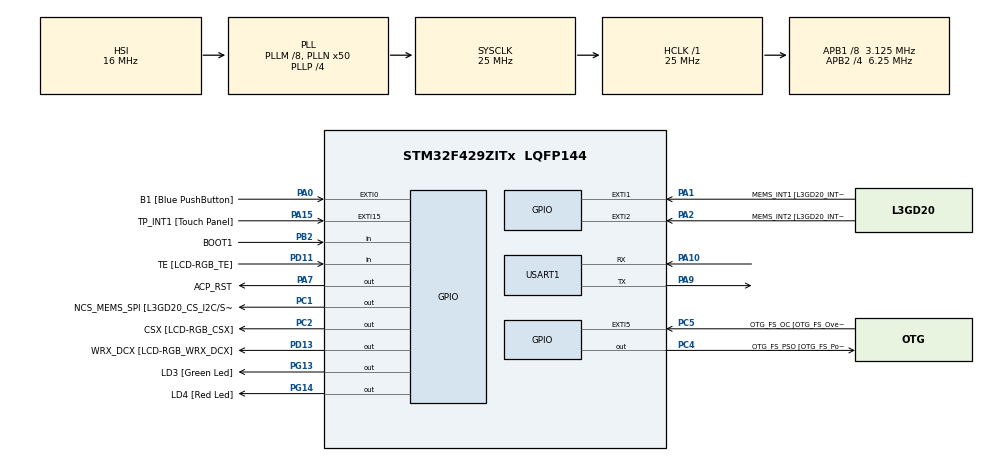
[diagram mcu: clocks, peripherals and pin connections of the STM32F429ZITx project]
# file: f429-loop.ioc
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Dma.Request0=USART1_TX
Dma.Request1=USART1_RX
Dma.USART1_RX.1.Direction=DMA_PERIPH_TO_MEMORY
Dma.USART1_RX.1.FIFOMode=DMA_FIFOMODE_DISABLE
Dma.USART1_RX.1.Instance=DMA2_Stream2
Dma.USART1_RX.1.MemDataAlignment=DMA_MDATAALIGN_BYTE
Dma.USART1_RX.1.MemInc=DMA_MINC_ENABLE
Dma.USART1_RX.1.Mode=DMA_CIRCULAR
Dma.USART1_RX.1.PeriphDataAlignment=DMA_PDATAALIGN_BYTE
Dma.USART1_RX.1.PeriphInc=DMA_PINC_DISABLE
Dma.USART1_RX.1.Priority=DMA_PRIORITY_LOW
Dma.USART1_TX.0.Direction=DMA_MEMORY_TO_PERIPH
Dma.USART1_TX.0.FIFOMode=DMA_FIFOMODE_DISABLE
Dma.USART1_TX.0.Instance=DMA2_Stream7
Dma.USART1_TX.0.MemDataAlignment=DMA_MDATAALIGN_BYTE
Dma.USART1_TX.0.MemInc=DMA_MINC_ENABLE
Dma.USART1_TX.0.Mode=DMA_NORMAL
Dma.USART1_TX.0.PeriphDataAlignment=DMA_PDATAALIGN_BYTE
Dma.USART1_TX.0.PeriphInc=DMA_PINC_DISABLE
Dma.USART1_TX.0.Priority=DMA_PRIORITY_LOW
Mcu.Family=STM32F4
Mcu.Name=STM32F429ZITx
Mcu.Package=LQFP144
NVIC.DMA2_Stream2_IRQn=true\:0\:0\:false\:false\:true\:false\:true\:true
NVIC.DMA2_Stream7_IRQn=true\:0\:0\:false\:false\:true\:false\:true\:true
NVIC.PriorityGroup=NVIC_PRIORITYGROUP_0
NVIC.TIM6_DAC_IRQn=true\:0\:0\:false\:false\:true\:true\:true\:true
NVIC.USART1_IRQn=true\:0\:0\:false\:false\:true\:true\:true\:true
PA0/WKUP.GPIO_Label=B1 [Blue PushButton]
PA0/WKUP.GPIO_ModeDefaultEXTI=GPIO_MODE_EVT_RISING
PA0/WKUP.GPIO_PuPd=GPIO_NOPULL
PA0/WKUP.Signal=GPXTI0
PA1.GPIO_Label=MEMS_INT1 [L3GD20_INT1]
PA1.GPIO_ModeDefaultEXTI=GPIO_MODE_EVT_RISING
PA1.GPIO_PuPd=GPIO_NOPULL
PA1.Signal=GPXTI1
PA10.Mode=Asynchronous
PA10.Signal=USART1_RX
PA15.GPIO_Label=TP_INT1 [Touch Panel]
PA15.GPIO_ModeDefaultEXTI=GPIO_MODE_EVT_RISING
PA15.GPIO_PuPd=GPIO_NOPULL
PA15.Signal=GPXTI15
PA2.GPIO_Label=MEMS_INT2 [L3GD20_INT2]
PA2.GPIO_ModeDefaultEXTI=GPIO_MODE_EVT_RISING
PA2.GPIO_PuPd=GPIO_NOPULL
PA2.Signal=GPXTI2
PA7.GPIO_Label=ACP_RST
PA7.GPIO_Mode=GPIO_MODE_OUTPUT_PP
PA7.GPIO_PuPd=GPIO_NOPULL
PA7.GPIO_Speed=GPIO_SPEED_FREQ_LOW
PA7.Signal=GPIO_Output
PA9.Mode=Asynchronous
PA9.Signal=USART1_TX
PB2/BOOT1.GPIO_Label=BOOT1
PB2/BOOT1.GPIO_Mode=GPIO_MODE_INPUT
PB2/BOOT1.GPIO_PuPd=GPIO_NOPULL
PB2/BOOT1.Signal=GPIO_Input
PC1.GPIO_Label=NCS_MEMS_SPI [L3GD20_CS_I2C/SPI]
PC1.GPIO_Mode=GPIO_MODE_OUTPUT_PP
PC1.GPIO_PuPd=GPIO_NOPULL
PC1.GPIO_Speed=GPIO_SPEED_FREQ_LOW
PC1.Signal=GPIO_Output
PC2.GPIO_Label=CSX [LCD-RGB_CSX]
PC2.GPIO_Mode=GPIO_MODE_OUTPUT_PP
PC2.GPIO_PuPd=GPIO_NOPULL
PC2.GPIO_Speed=GPIO_SPEED_FREQ_LOW
PC2.Signal=GPIO_Output
PC4.GPIO_Label=OTG_FS_PSO [OTG_FS_PowerSwitchOn]
PC4.GPIO_Mode=GPIO_MODE_OUTPUT_PP
PC4.GPIO_PuPd=GPIO_NOPULL
PC4.GPIO_Speed=GPIO_SPEED_FREQ_LOW
PC4.Signal=GPIO_Output
PC5.GPIO_Label=OTG_FS_OC [OTG_FS_OverCurrent]
PC5.GPIO_ModeDefaultEXTI=GPIO_MODE_EVT_RISING
PC5.Signal=GPXTI5
PD11.GPIO_Label=TE [LCD-RGB_TE]
PD11.GPIO_Mode=GPIO_MODE_INPUT
PD11.GPIO_PuPd=GPIO_NOPULL
PD11.Signal=GPIO_Input
PD13.GPIO_Label=WRX_DCX [LCD-RGB_WRX_DCX]
PD13.GPIO_Mode=GPIO_MODE_OUTPUT_PP
PD13.GPIO_PuPd=GPIO_NOPULL
PD13.GPIO_Speed=GPIO_SPEED_FREQ_LOW
PD13.Signal=GPIO_Output
PG13.GPIO_Label=LD3 [Green Led]
PG13.GPIO_Mode=GPIO_MODE_OUTPUT_PP
PG13.GPIO_PuPd=GPIO_NOPULL
PG13.GPIO_Speed=GPIO_SPEED_FREQ_LOW
PG13.Signal=GPIO_Output
PG14.GPIO_Label=LD4 [Red Led]
PG14.GPIO_Mode=GPIO_MODE_OUTPUT_PP
PG14.GPIO_PuPd=GPIO_NOPULL
PG14.GPIO_Speed=GPIO_SPEED_FREQ_LOW
PG14.Signal=GPIO_Output
ProjectManager.HeapSize=0x200
ProjectManager.StackSize=0x400
ProjectManager.TargetToolchain=STM32CubeIDE
RCC.48MHZClocksFreq_Value=14285714.285714285
RCC.AHBFreq_Value=25000000
RCC.APB1CLKDivider=RCC_HCLK_DIV8
RCC.APB1Freq_Value=3125000
RCC.APB1TimFreq_Value=6250000
RCC.APB2CLKDivider=RCC_HCLK_DIV4
RCC.APB2Freq_Value=6250000
RCC.APB2TimFreq_Value=12500000
RCC.CortexFreq_Value=25000000
RCC.HCLKFreq_Value=25000000
RCC.HSE_VALUE=8000000
RCC.HSI_VALUE=16000000
RCC.LSE_VALUE=32768
RCC.PLLM=8
RCC.PLLN=50
RCC.PLLP=RCC_PLLP_DIV4
RCC.PLLQ=7
RCC.SYSCLKFreq_VALUE=25000000
RCC.SYSCLKSource=RCC_SYSCLKSOURCE_PLLCLK
RCC.VCOOutputFreq_Value=100000000
TIM6.Period=24999
USART1.VirtualMode=VM_ASYNC
VP_TIM6_VS_ClockSourceINT.Mode=Enable_Timer
board=STM32F429I-DISC1

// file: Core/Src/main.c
/* USER CODE BEGIN Header */
/**
  ******************************************************************************
  * @file           : main.c
  * @brief          : Main program body
  ******************************************************************************
  * @attention
  *
  * Copyright (c) 2026 STMicroelectronics.
  * All rights reserved.
  *
  * This software is licensed under terms that can be found in the LICENSE file
  * in the root directory of this software component.
  * If no LICENSE file comes with this software, it is provided AS-IS.
  *
  ******************************************************************************
  */
/* USER CODE END Header */
#include "main.h"

/* USER CODE BEGIN Includes */
#include "superloop.h"
extern int board_init(void);
/* USER CODE END Includes */

TIM_HandleTypeDef htim6;

UART_HandleTypeDef huart1;
DMA_HandleTypeDef hdma_usart1_tx;
DMA_HandleTypeDef hdma_usart1_rx;

void SystemClock_Config(void);
static void MX_GPIO_Init(void);
static void MX_DMA_Init(void);
static void MX_USART1_UART_Init(void);
static void MX_TIM6_Init(void);

int main(void)
{

  /* MCU Configuration--------------------------------------------------------*/

  /* Reset of all peripherals, Initializes the Flash interface and the Systick. */
  HAL_Init();

  /* Configure the system clock */
  SystemClock_Config();

  /* Initialize all configured peripherals */
  MX_GPIO_Init();
  MX_DMA_Init();
  MX_USART1_UART_Init();
  MX_TIM6_Init();
  /* USER CODE BEGIN 2 */
  board_init();
  /* USER CODE END 2 */

  /* Infinite loop */
  while (1)
  {

    /* USER CODE BEGIN 3 */
    sloop_dispatch();
  }
  /* USER CODE END 3 */
}

void SystemClock_Config(void)
{
  RCC_OscInitTypeDef RCC_OscInitStruct = {0};
  RCC_ClkInitTypeDef RCC_ClkInitStruct = {0};

  /** Configure the main internal regulator output voltage
  */
  __HAL_RCC_PWR_CLK_ENABLE();
  __HAL_PWR_VOLTAGESCALING_CONFIG(PWR_REGULATOR_VOLTAGE_SCALE3);

  /** Initializes the RCC Oscillators according to the specified parameters
  * in the RCC_OscInitTypeDef structure.
  */
  RCC_OscInitStruct.OscillatorType = RCC_OSCILLATORTYPE_HSI;
  RCC_OscInitStruct.HSIState = RCC_HSI_ON;
  RCC_OscInitStruct.HSICalibrationValue = RCC_HSICALIBRATION_DEFAULT;
  RCC_OscInitStruct.PLL.PLLState = RCC_PLL_ON;
  RCC_OscInitStruct.PLL.PLLSource = RCC_PLLSOURCE_HSI;
  RCC_OscInitStruct.PLL.PLLM = 8;
  RCC_OscInitStruct.PLL.PLLN = 50;
  RCC_OscInitStruct.PLL.PLLP = RCC_PLLP_DIV4;
  RCC_OscInitStruct.PLL.PLLQ = 7;
  if (HAL_RCC_OscConfig(&RCC_OscInitStruct) != HAL_OK)
  {
    Error_Handler();
  }

  /** Initializes the CPU, AHB and APB buses clocks
  */
  RCC_ClkInitStruct.ClockType = RCC_CLOCKTYPE_HCLK|RCC_CLOCKTYPE_SYSCLK
                              |RCC_CLOCKTYPE_PCLK1|RCC_CLOCKTYPE_PCLK2;
  RCC_ClkInitStruct.SYSCLKSource = RCC_SYSCLKSOURCE_PLLCLK;
  RCC_ClkInitStruct.AHBCLKDivider = RCC_SYSCLK_DIV1;
  RCC_ClkInitStruct.APB1CLKDivider = RCC_HCLK_DIV8;
  RCC_ClkInitStruct.APB2CLKDivider = RCC_HCLK_DIV4;

  if (HAL_RCC_ClockConfig(&RCC_ClkInitStruct, FLASH_LATENCY_0) != HAL_OK)
  {
    Error_Handler();
  }
}

static void MX_TIM6_Init(void)
{

  TIM_MasterConfigTypeDef sMasterConfig = {0};

  htim6.Instance = TIM6;
  htim6.Init.Prescaler = 0;
  htim6.Init.CounterMode = TIM_COUNTERMODE_UP;
  htim6.Init.Period = 24999;
  htim6.Init.AutoReloadPreload = TIM_AUTORELOAD_PRELOAD_DISABLE;
  if (HAL_TIM_Base_Init(&htim6) != HAL_OK)
  {
    Error_Handler();
  }
  sMasterConfig.MasterOutputTrigger = TIM_TRGO_RESET;
  sMasterConfig.MasterSlaveMode = TIM_MASTERSLAVEMODE_DISABLE;
  if (HAL_TIMEx_MasterConfigSynchronization(&htim6, &sMasterConfig) != HAL_OK)
  {
    Error_Handler();
  }

}

static void MX_USART1_UART_Init(void)
{

  huart1.Instance = USART1;
  huart1.Init.BaudRate = 115200;
  huart1.Init.WordLength = UART_WORDLENGTH_8B;
  huart1.Init.StopBits = UART_STOPBITS_1;
  huart1.Init.Parity = UART_PARITY_NONE;
  huart1.Init.Mode = UART_MODE_TX_RX;
  huart1.Init.HwFlowCtl = UART_HWCONTROL_NONE;
  huart1.Init.OverSampling = UART_OVERSAMPLING_16;
  if (HAL_UART_Init(&huart1) != HAL_OK)
  {
    Error_Handler();
  }

}

static void MX_DMA_Init(void)
{

  /* DMA controller clock enable */
  __HAL_RCC_DMA2_CLK_ENABLE();

  /* DMA interrupt init */
  /* DMA2_Stream2_IRQn interrupt configuration */
  HAL_NVIC_SetPriority(DMA2_Stream2_IRQn, 0, 0);
  HAL_NVIC_EnableIRQ(DMA2_Stream2_IRQn);
  /* DMA2_Stream7_IRQn interrupt configuration */
  HAL_NVIC_SetPriority(DMA2_Stream7_IRQn, 0, 0);
  HAL_NVIC_EnableIRQ(DMA2_Stream7_IRQn);

}

static void MX_GPIO_Init(void)
{
  GPIO_InitTypeDef GPIO_InitStruct = {0};

  /* GPIO Ports Clock Enable */
  __HAL_RCC_GPIOC_CLK_ENABLE();
  __HAL_RCC_GPIOA_CLK_ENABLE();
  __HAL_RCC_GPIOB_CLK_ENABLE();
  __HAL_RCC_GPIOD_CLK_ENABLE();
  __HAL_RCC_GPIOG_CLK_ENABLE();

  /*Configure GPIO pin Output Level */
  HAL_GPIO_WritePin(GPIOC, NCS_MEMS_SPI_Pin|CSX_Pin|OTG_FS_PSO_Pin, GPIO_PIN_RESET);

  /*Configure GPIO pin Output Level */
  HAL_GPIO_WritePin(ACP_RST_GPIO_Port, ACP_RST_Pin, GPIO_PIN_RESET);

  /*Configure GPIO pin Output Level */
  HAL_GPIO_WritePin(WRX_DCX_GPIO_Port, WRX_DCX_Pin, GPIO_PIN_RESET);

  /*Configure GPIO pin Output Level */
  HAL_GPIO_WritePin(GPIOG, LD3_Pin|LD4_Pin, GPIO_PIN_RESET);

  /*Configure GPIO pins : NCS_MEMS_SPI_Pin CSX_Pin OTG_FS_PSO_Pin */
  GPIO_InitStruct.Pin = NCS_MEMS_SPI_Pin|CSX_Pin|OTG_FS_PSO_Pin;
  GPIO_InitStruct.Mode = GPIO_MODE_OUTPUT_PP;
  GPIO_InitStruct.Pull = GPIO_NOPULL;
  GPIO_InitStruct.Speed = GPIO_SPEED_FREQ_LOW;
  HAL_GPIO_Init(GPIOC, &GPIO_InitStruct);

  /*Configure GPIO pins : B1_Pin MEMS_INT1_Pin MEMS_INT2_Pin TP_INT1_Pin */
  GPIO_InitStruct.Pin = B1_Pin|MEMS_INT1_Pin|MEMS_INT2_Pin|TP_INT1_Pin;
  GPIO_InitStruct.Mode = GPIO_MODE_EVT_RISING;
  GPIO_InitStruct.Pull = GPIO_NOPULL;
  HAL_GPIO_Init(GPIOA, &GPIO_InitStruct);

  /*Configure GPIO pin : ACP_RST_Pin */
  GPIO_InitStruct.Pin = ACP_RST_Pin;
  GPIO_InitStruct.Mode = GPIO_MODE_OUTPUT_PP;
  GPIO_InitStruct.Pull = GPIO_NOPULL;
  GPIO_InitStruct.Speed = GPIO_SPEED_FREQ_LOW;
  HAL_GPIO_Init(ACP_RST_GPIO_Port, &GPIO_InitStruct);

  /*Configure GPIO pin : OTG_FS_OC_Pin */
  GPIO_InitStruct.Pin = OTG_FS_OC_Pin;
  GPIO_InitStruct.Mode = GPIO_MODE_EVT_RISING;
  GPIO_InitStruct.Pull = GPIO_NOPULL;
  HAL_GPIO_Init(OTG_FS_OC_GPIO_Port, &GPIO_InitStruct);

  /*Configure GPIO pin : BOOT1_Pin */
  GPIO_InitStruct.Pin = BOOT1_Pin;
  GPIO_InitStruct.Mode = GPIO_MODE_INPUT;
  GPIO_InitStruct.Pull = GPIO_NOPULL;
  HAL_GPIO_Init(BOOT1_GPIO_Port, &GPIO_InitStruct);

  /*Configure GPIO pin : TE_Pin */
  GPIO_InitStruct.Pin = TE_Pin;
  GPIO_InitStruct.Mode = GPIO_MODE_INPUT;
  GPIO_InitStruct.Pull = GPIO_NOPULL;
  HAL_GPIO_Init(TE_GPIO_Port, &GPIO_InitStruct);

  /*Configure GPIO pin : WRX_DCX_Pin */
  GPIO_InitStruct.Pin = WRX_DCX_Pin;
  GPIO_InitStruct.Mode = GPIO_MODE_OUTPUT_PP;
  GPIO_InitStruct.Pull = GPIO_NOPULL;
  GPIO_InitStruct.Speed = GPIO_SPEED_FREQ_LOW;
  HAL_GPIO_Init(WRX_DCX_GPIO_Port, &GPIO_InitStruct);

  /*Configure GPIO pins : LD3_Pin LD4_Pin */
  GPIO_InitStruct.Pin = LD3_Pin|LD4_Pin;
  GPIO_InitStruct.Mode = GPIO_MODE_OUTPUT_PP;
  GPIO_InitStruct.Pull = GPIO_NOPULL;
  GPIO_InitStruct.Speed = GPIO_SPEED_FREQ_LOW;
  HAL_GPIO_Init(GPIOG, &GPIO_InitStruct);

}

/* USER CODE BEGIN 4 */
void HAL_SYSTICK_Callback(void)
{
	sloop_tick();
}
/* USER CODE END 4 */

void Error_Handler(void)
{
  __disable_irq();
  while (1)
  {
  }
}
